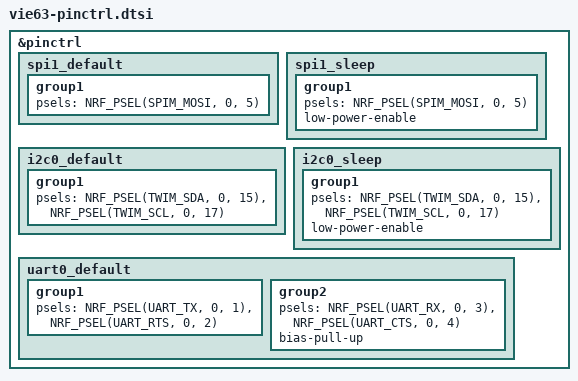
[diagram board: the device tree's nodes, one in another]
/*
* Copyright (c) 2022 The ZMK Contributors
* SPDX-License-Identifier: MIT
*/

&pinctrl {
        spi1_default: spi1_default {
        group1 {
            psels = <NRF_PSEL(SPIM_MOSI, 0, 5)>;
        };
    };
    spi1_sleep: spi1_sleep {
        group1 {
            psels = <NRF_PSEL(SPIM_MOSI, 0, 5)>;
            low-power-enable;
        };
    };
        i2c0_default: i2c0_default {
                group1 {
                        psels = <NRF_PSEL(TWIM_SDA, 0, 15)>,
                                <NRF_PSEL(TWIM_SCL, 0, 17)>;
                };
        };

        i2c0_sleep: i2c0_sleep {
                group1 {
                        psels = <NRF_PSEL(TWIM_SDA, 0, 15)>,
                                <NRF_PSEL(TWIM_SCL, 0, 17)>;
                        low-power-enable;
                };
        };

     /* configuration for uart0 device, default state */
    uart0_default: uart0_default {
        group1 {
            /* configure P0.1 as UART_TX and P0.2 as UART_RTS */
            psels = <NRF_PSEL(UART_TX, 0, 1)>, <NRF_PSEL(UART_RTS, 0, 2)>;
        };
        group2 {
            /* configure P0.3 as UART_RX and P0.4 as UART_CTS */
            psels = <NRF_PSEL(UART_RX, 0, 3)>, <NRF_PSEL(UART_CTS, 0, 4)>;
            /* both P0.3 and P0.4 are configured with pull-up */
            bias-pull-up;
        };
    };
};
